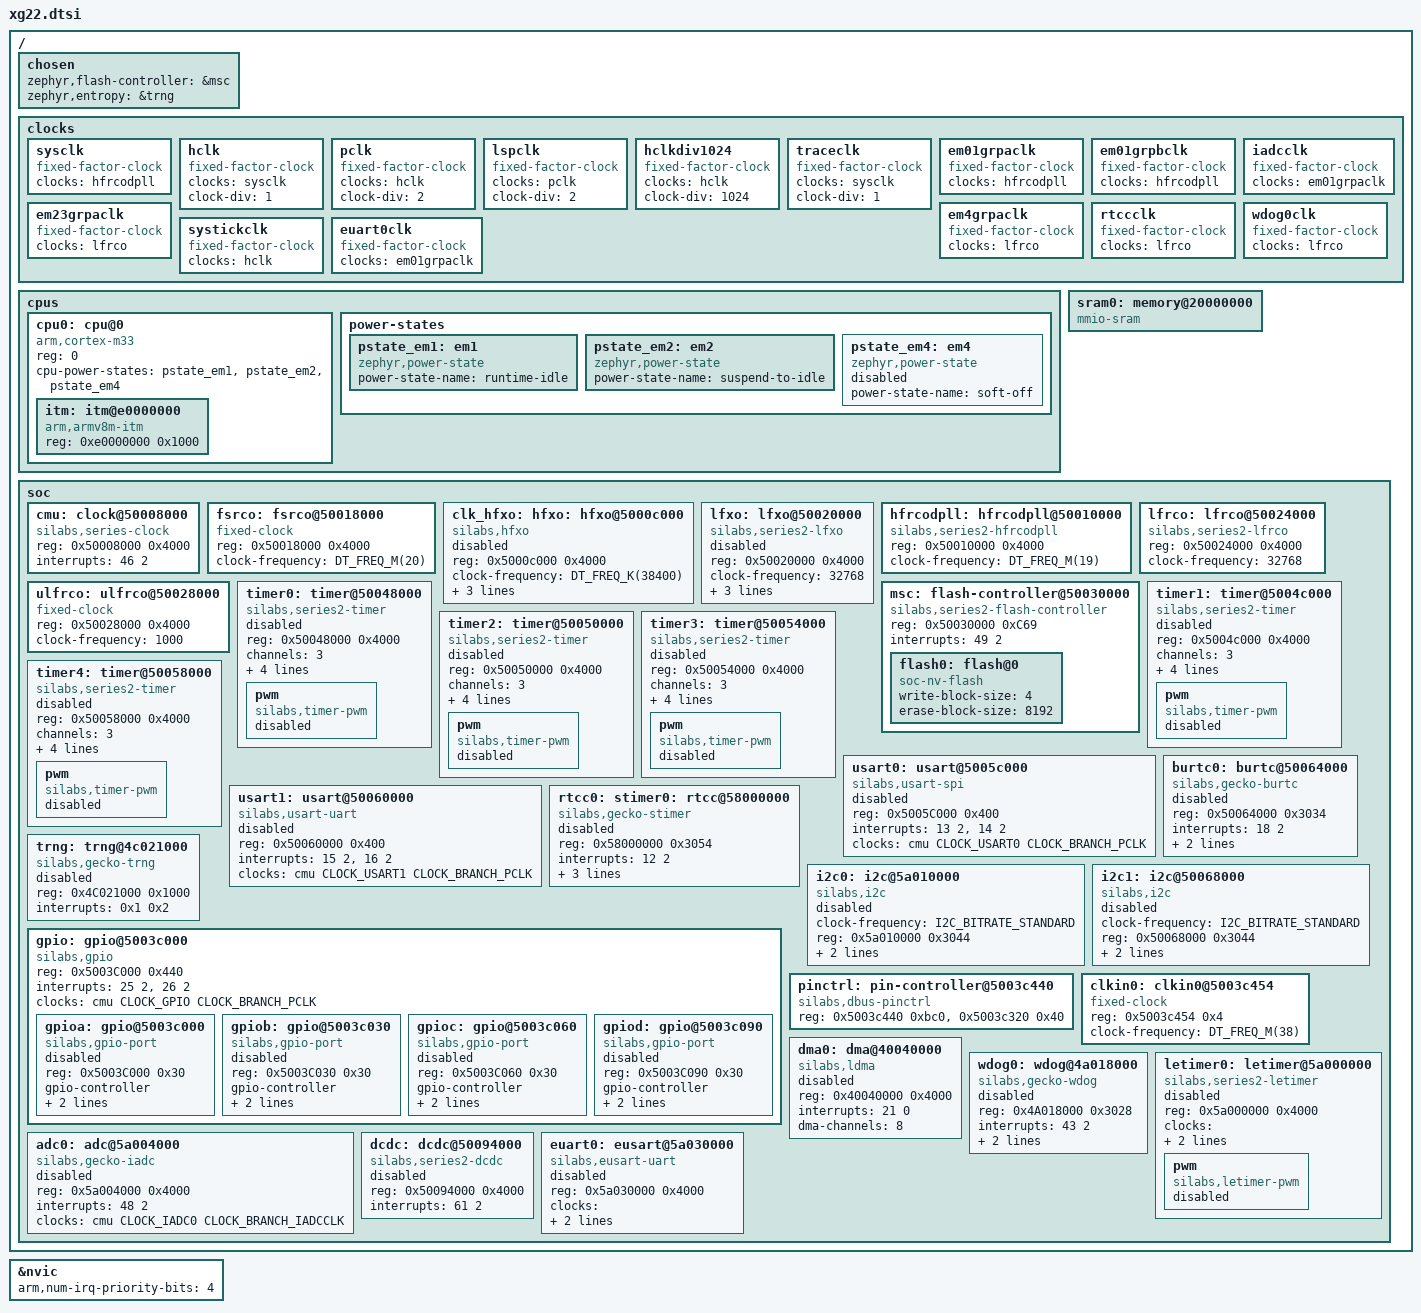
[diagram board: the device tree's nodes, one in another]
/*
 * Copyright (c) 2021 Sateesh Kotapati
 * Copyright (c) 2025 Silicon Laboratories Inc.
 *
 * SPDX-License-Identifier: Apache-2.0
 */

#include <arm/armv8-m.dtsi>
#include <zephyr/dt-bindings/adc/adc.h>
#include <zephyr/dt-bindings/clock/silabs/xg22-clock.h>
#include <zephyr/dt-bindings/dma/silabs/xg22-dma.h>
#include <zephyr/dt-bindings/gpio/gpio.h>
#include <zephyr/dt-bindings/i2c/i2c.h>
#include <freq.h>

/ {
	chosen {
		zephyr,flash-controller = &msc;
		zephyr,entropy = &trng;
	};

	clocks {
		sysclk: sysclk {
			#clock-cells = <0>;
			compatible = "fixed-factor-clock";
			clocks = <&hfrcodpll>;
		};

		hclk: hclk {
			#clock-cells = <0>;
			compatible = "fixed-factor-clock";
			clocks = <&sysclk>;
			/* Divisors 1, 2, 4, 8, 16 allowed */
			clock-div = <1>;
		};

		pclk: pclk {
			#clock-cells = <0>;
			compatible = "fixed-factor-clock";
			clocks = <&hclk>;
			/* Divisors 1, 2 allowed */
			clock-div = <2>;
		};

		lspclk: lspclk {
			#clock-cells = <0>;
			compatible = "fixed-factor-clock";
			clocks = <&pclk>;
			/* Fixed divisor of 2 */
			clock-div = <2>;
		};

		hclkdiv1024: hclkdiv1024 {
			#clock-cells = <0>;
			compatible = "fixed-factor-clock";
			clocks = <&hclk>;
			/* Fixed divisor of 1024 */
			clock-div = <1024>;
		};

		traceclk: traceclk {
			#clock-cells = <0>;
			compatible = "fixed-factor-clock";
			clocks = <&sysclk>;
			/* Divisors 1, 2, 3, 4 allowed */
			clock-div = <1>;
		};

		em01grpaclk: em01grpaclk {
			#clock-cells = <0>;
			compatible = "fixed-factor-clock";
			clocks = <&hfrcodpll>;
		};

		em01grpbclk: em01grpbclk {
			#clock-cells = <0>;
			compatible = "fixed-factor-clock";
			clocks = <&hfrcodpll>;
		};

		iadcclk: iadcclk {
			#clock-cells = <0>;
			compatible = "fixed-factor-clock";
			clocks = <&em01grpaclk>;
		};

		em23grpaclk: em23grpaclk {
			#clock-cells = <0>;
			compatible = "fixed-factor-clock";
			clocks = <&lfrco>;
		};

		em4grpaclk: em4grpaclk {
			#clock-cells = <0>;
			compatible = "fixed-factor-clock";
			clocks = <&lfrco>;
		};

		rtccclk: rtccclk {
			#clock-cells = <0>;
			compatible = "fixed-factor-clock";
			clocks = <&lfrco>;
		};

		wdog0clk: wdog0clk {
			#clock-cells = <0>;
			compatible = "fixed-factor-clock";
			clocks = <&lfrco>;
		};

		systickclk: systickclk {
			#clock-cells = <0>;
			compatible = "fixed-factor-clock";
			clocks = <&hclk>;
		};

		euart0clk: euart0clk {
			#clock-cells = <0>;
			compatible = "fixed-factor-clock";
			clocks = <&em01grpaclk>;
		};
	};

	cpus {
		#address-cells = <1>;
		#size-cells = <0>;

		cpu0: cpu@0 {
			device_type = "cpu";
			compatible = "arm,cortex-m33";
			reg = <0>;
			/*
			 * EM1 is enabled by default because it is
			 * unconditionally safe.
			 *
			 * EM2/3 can be enabled by the board code if proper
			 * timing configuration is ensured:
			 * - for EM2, EM3: BURTC used as sys_clock
			 * - for EM3: BURTC clocked from ULFRCO
			 * Using BURTC as sys_clock instead of SysTick
			 * has implications on system performance. Read
			 * KConfig documentation entry before enabling it.
			 *
			 * The minimum residency and exit latency is
			 * managed by sl_power_manager on S2 devices.
			 */
			cpu-power-states = <&pstate_em1 &pstate_em2 &pstate_em4>;
			#address-cells = <1>;
			#size-cells = <1>;

			itm: itm@e0000000 {
				compatible = "arm,armv8m-itm";
				reg = <0xe0000000 0x1000>;
			};
		};

		power-states {
			/*
			 * EM1 is a basic "CPU WFI idle", all high-freq clocks remain
			 * enabled.
			 */
			pstate_em1: em1 {
				compatible = "zephyr,power-state";
				power-state-name = "runtime-idle";
				/* HFXO remains active */
			};

			/*
			 * EM2 is a deepsleep with HF clocks disabled by HW, voltages
			 * scaled down, etc.
			 */
			pstate_em2: em2 {
				compatible = "zephyr,power-state";
				power-state-name = "suspend-to-idle";
			};

			/*
			 * EM4 is a shutdown state where all clocks are off. The device
			 * is reset on wakeup from EM4.
			 */
			pstate_em4: em4 {
				compatible = "zephyr,power-state";
				power-state-name = "soft-off";
				status = "disabled";
			};
		};
	};

	sram0: memory@20000000 {
		compatible = "mmio-sram";
	};

	soc {
		cmu: clock@50008000 {
			compatible = "silabs,series-clock";
			reg = <0x50008000 0x4000>;
			interrupts = <46 2>;
			interrupt-names = "cmu";
			status = "okay";
			#clock-cells = <2>;
		};

		fsrco: fsrco@50018000 {
			#clock-cells = <0>;
			compatible = "fixed-clock";
			reg = <0x50018000 0x4000>;
			clock-frequency = <DT_FREQ_M(20)>;
		};

		clk_hfxo: hfxo: hfxo@5000c000 {
			#clock-cells = <0>;
			compatible = "silabs,hfxo";
			reg = <0x5000c000 0x4000>;
			clock-frequency = <DT_FREQ_K(38400)>;
			interrupts = <44 0>;
			interrupt-names = "hfxo";
			ctune = <140>;
			precision = <50>;
			status = "disabled";
		};

		lfxo: lfxo@50020000 {
			#clock-cells = <0>;
			compatible = "silabs,series2-lfxo";
			reg = <0x50020000 0x4000>;
			clock-frequency = <32768>;
			ctune = <63>;
			precision = <50>;
			timeout = <4096>;
			status = "disabled";
		};

		hfrcodpll: hfrcodpll@50010000 {
			#clock-cells = <0>;
			compatible = "silabs,series2-hfrcodpll";
			reg = <0x50010000 0x4000>;
			clock-frequency = <DT_FREQ_M(19)>;
		};

		lfrco: lfrco@50024000 {
			#clock-cells = <0>;
			compatible = "silabs,series2-lfrco";
			reg = <0x50024000 0x4000>;
			clock-frequency = <32768>;
		};

		ulfrco: ulfrco@50028000 {
			#clock-cells = <0>;
			compatible = "fixed-clock";
			reg = <0x50028000 0x4000>;
			clock-frequency = <1000>;
		};

		msc: flash-controller@50030000 {
			compatible = "silabs,series2-flash-controller";
			reg = <0x50030000 0xC69>;
			interrupts = <49 2>;
			#address-cells = <1>;
			#size-cells = <1>;

			flash0: flash@0 {
				compatible = "soc-nv-flash";
				write-block-size = <4>;
				erase-block-size = <8192>;
			};
		};

		timer0: timer@50048000 {
			compatible = "silabs,series2-timer";
			reg = <0x50048000 0x4000>;
			channels = <3>;
			clocks = <&cmu CLOCK_TIMER0 CLOCK_BRANCH_EM01GRPACLK>;
			counter-size = <32>;
			interrupts = <7 2>;
			status = "disabled";

			pwm {
				compatible = "silabs,timer-pwm";
				#pwm-cells = <3>;
				status = "disabled";
			};
		};

		timer1: timer@5004c000 {
			compatible = "silabs,series2-timer";
			reg = <0x5004c000 0x4000>;
			channels = <3>;
			clocks = <&cmu CLOCK_TIMER1 CLOCK_BRANCH_EM01GRPACLK>;
			counter-size = <16>;
			interrupts = <8 2>;
			status = "disabled";

			pwm {
				compatible = "silabs,timer-pwm";
				#pwm-cells = <3>;
				status = "disabled";
			};
		};

		timer2: timer@50050000 {
			compatible = "silabs,series2-timer";
			reg = <0x50050000 0x4000>;
			channels = <3>;
			clocks = <&cmu CLOCK_TIMER2 CLOCK_BRANCH_EM01GRPACLK>;
			counter-size = <16>;
			interrupts = <9 2>;
			status = "disabled";

			pwm {
				compatible = "silabs,timer-pwm";
				#pwm-cells = <3>;
				status = "disabled";
			};
		};

		timer3: timer@50054000 {
			compatible = "silabs,series2-timer";
			reg = <0x50054000 0x4000>;
			channels = <3>;
			clocks = <&cmu CLOCK_TIMER3 CLOCK_BRANCH_EM01GRPACLK>;
			counter-size = <16>;
			interrupts = <10 2>;
			status = "disabled";

			pwm {
				compatible = "silabs,timer-pwm";
				#pwm-cells = <3>;
				status = "disabled";
			};
		};

		timer4: timer@50058000 {
			compatible = "silabs,series2-timer";
			reg = <0x50058000 0x4000>;
			channels = <3>;
			clocks = <&cmu CLOCK_TIMER4 CLOCK_BRANCH_EM01GRPACLK>;
			counter-size = <16>;
			interrupts = <11 2>;
			status = "disabled";

			pwm {
				compatible = "silabs,timer-pwm";
				#pwm-cells = <3>;
				status = "disabled";
			};
		};

		usart0: usart@5005c000 {
			compatible = "silabs,usart-spi";
			reg = <0x5005C000 0x400>;
			interrupts = <13 2>, <14 2>;
			interrupt-names = "rx", "tx";
			clocks = <&cmu CLOCK_USART0 CLOCK_BRANCH_PCLK>;
			#address-cells = <1>;
			#size-cells = <0>;
			status = "disabled";
		};

		usart1: usart@50060000 {
			compatible = "silabs,usart-uart";
			reg = <0x50060000 0x400>;
			interrupts = <15 2>, <16 2>;
			interrupt-names = "rx", "tx";
			clocks = <&cmu CLOCK_USART1 CLOCK_BRANCH_PCLK>;
			status = "disabled";
		};

		burtc0: burtc@50064000 {
			compatible = "silabs,gecko-burtc";
			reg = <0x50064000 0x3034>;
			interrupts = <18 2>;
			clocks = <&cmu CLOCK_BURTC CLOCK_BRANCH_EM4GRPACLK>;
			status = "disabled";
		};

		rtcc0: stimer0: rtcc@58000000 {
			compatible = "silabs,gecko-stimer";
			reg = <0x58000000 0x3054>;
			interrupts = <12 2>;
			interrupt-names = "rtcc";
			clocks = <&cmu CLOCK_RTCC CLOCK_BRANCH_RTCCCLK>;
			clock-frequency = <32768>;
			prescaler = <1>;
			status = "disabled";
		};

		trng: trng@4c021000 {
			compatible = "silabs,gecko-trng";
			reg = <0x4C021000 0x1000>;
			status = "disabled";
			interrupts = <0x1 0x2>;
		};

		i2c0: i2c@5a010000 {
			compatible = "silabs,i2c";
			clock-frequency = <I2C_BITRATE_STANDARD>;
			reg = <0x5a010000 0x3044>;
			interrupts = <27 2>;
			clocks = <&cmu CLOCK_I2C0 CLOCK_BRANCH_LSPCLK>;
			#address-cells = <1>;
			#size-cells = <0>;
			status = "disabled";
		};

		i2c1: i2c@50068000 {
			compatible = "silabs,i2c";
			clock-frequency = <I2C_BITRATE_STANDARD>;
			reg = <0x50068000 0x3044>;
			interrupts = <28 2>;
			clocks = <&cmu CLOCK_I2C1 CLOCK_BRANCH_PCLK>;
			#address-cells = <1>;
			#size-cells = <0>;
			status = "disabled";
		};

		gpio: gpio@5003c000 {
			compatible = "silabs,gpio";
			reg = <0x5003C000 0x440>;
			ranges;
			interrupts = <25 2>, <26 2>;
			interrupt-names = "gpio_odd", "gpio_even";
			clocks = <&cmu CLOCK_GPIO CLOCK_BRANCH_PCLK>;
			#address-cells = <1>;
			#size-cells = <1>;

			gpioa: gpio@5003c000 {
				compatible = "silabs,gpio-port";
				reg = <0x5003C000 0x30>;
				gpio-controller;
				#gpio-cells = <2>;
				silabs,wakeup-ints = <0>;
				silabs,wakeup-pins = <5>;
				status = "disabled";
			};

			gpiob: gpio@5003c030 {
				compatible = "silabs,gpio-port";
				reg = <0x5003C030 0x30>;
				gpio-controller;
				#gpio-cells = <2>;
				silabs,wakeup-ints = <3>, <4>;
				silabs,wakeup-pins = <1>, <3>;
				status = "disabled";
			};

			gpioc: gpio@5003c060 {
				compatible = "silabs,gpio-port";
				reg = <0x5003C060 0x30>;
				gpio-controller;
				#gpio-cells = <2>;
				silabs,wakeup-ints = <6>, <7>, <8>;
				silabs,wakeup-pins = <0>, <5>, <7>;
				status = "disabled";
			};

			gpiod: gpio@5003c090 {
				compatible = "silabs,gpio-port";
				reg = <0x5003C090 0x30>;
				gpio-controller;
				#gpio-cells = <2>;
				silabs,wakeup-ints = <9>;
				silabs,wakeup-pins = <2>;
				status = "disabled";
			};
		};

		pinctrl: pin-controller@5003c440 {
			compatible = "silabs,dbus-pinctrl";
			reg = <0x5003c440 0xbc0>, <0x5003c320 0x40>;
			reg-names = "dbus", "abus";
		};

		clkin0: clkin0@5003c454 {
			#clock-cells = <0>;
			compatible = "fixed-clock";
			reg = <0x5003c454 0x4>;
			clock-frequency = <DT_FREQ_M(38)>;
		};

		dma0: dma@40040000 {
			compatible = "silabs,ldma";
			reg = <0x40040000 0x4000>;
			interrupts = <21 0>;
			#dma-cells = <1>;
			dma-channels = <8>;
			status = "disabled";
		};

		wdog0: wdog@4a018000 {
			compatible = "silabs,gecko-wdog";
			reg = <0x4A018000 0x3028>;
			interrupts = <43 2>;
			clocks = <&cmu CLOCK_WDOG0 CLOCK_BRANCH_WDOG0CLK>;
			peripheral-id = <0>;
			status = "disabled";
		};

		letimer0: letimer@5a000000 {
			compatible = "silabs,series2-letimer";
			reg = <0x5a000000 0x4000>;
			clocks = <&cmu CLOCK_LETIMER0 CLOCK_BRANCH_EM23GRPACLK>;
			interrupts = <19 2>;
			status = "disabled";

			pwm {
				compatible = "silabs,letimer-pwm";
				#pwm-cells = <3>;
				status = "disabled";
			};
		};

		adc0: adc@5a004000 {
			compatible = "silabs,gecko-iadc";
			reg = <0x5a004000 0x4000>;
			interrupts = <48 2>;
			clocks = <&cmu CLOCK_IADC0 CLOCK_BRANCH_IADCCLK>;
			status = "disabled";
			#io-channel-cells = <1>;
		};

		dcdc: dcdc@50094000 {
			compatible = "silabs,series2-dcdc";
			reg = <0x50094000 0x4000>;
			interrupts = <61 2>;
			status = "disabled";
		};

		euart0: eusart@5a030000 {
			compatible = "silabs,eusart-uart";
			reg = <0x5a030000 0x4000>;
			clocks = <&cmu CLOCK_EUART0 CLOCK_BRANCH_EUART0CLK>;
			interrupt-names = "rx", "tx";
			interrupts = <62 2>, <63 2>;
			status = "disabled";
		};
	};
};

&nvic {
	arm,num-irq-priority-bits = <4>;
};
